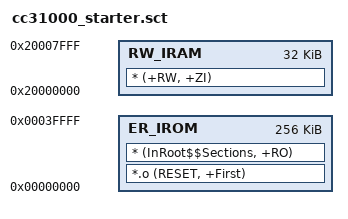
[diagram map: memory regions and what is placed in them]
;******************************************************************************
;
; cc31000_starter.sct - Linker configuration file for cc31000_starter.
;
; Copyright (c) 2014 Texas Instruments Incorporated.  All rights reserved.
; TI Information - Selective Disclosure
;
;******************************************************************************

LR_IROM 0x00000000 0x00040000
{
    ;
    ; Specify the Execution Address of the code and the size.
    ;
    ER_IROM 0x00000000 0x00040000
    {
        *.o (RESET, +First)
        * (InRoot$$Sections, +RO)
    }

    ;
    ; Specify the Execution Address of the data area.
    ;
    RW_IRAM 0x20000000 0x00008000
    {
        ;
        ; Uncomment the following line in order to use IntRegister().
        ;
        ;* (vtable, +First)
        * (+RW, +ZI)
    }
}
